# DA14683 register map
Vendor: Dialog; Series: DA14683; File version: 1.2
CPU: CM0 r1p0, little endian, MPU, FPU, 3 interrupt priority bits
Registers are 16-bit, read-write, reset 0x0 unless marked. A register's access mark holds for its fields unless they carry their own. Offsets are from the block's base; [hi:lo] are bit positions; {n}, {i} and the like mark numbered series.

## DEM — DEM registers
Base 0x50002E00
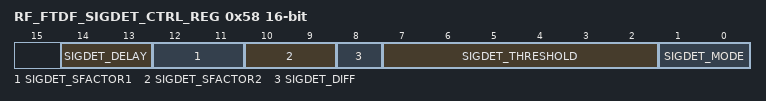
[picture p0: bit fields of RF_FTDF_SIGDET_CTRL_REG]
0x58 RF_FTDF_SIGDET_CTRL_REG
  [14:13] SIGDET_DELAY, [12:11] SIGDET_SFACTOR1, [10:9] SIGDET_SFACTOR2, [8] SIGDET_DIFF, [7:2] SIGDET_THRESHOLD, [1:0] SIGDET_MODE

## GP_TIMERS — GP_TIMERS registers
Base 0x50003400
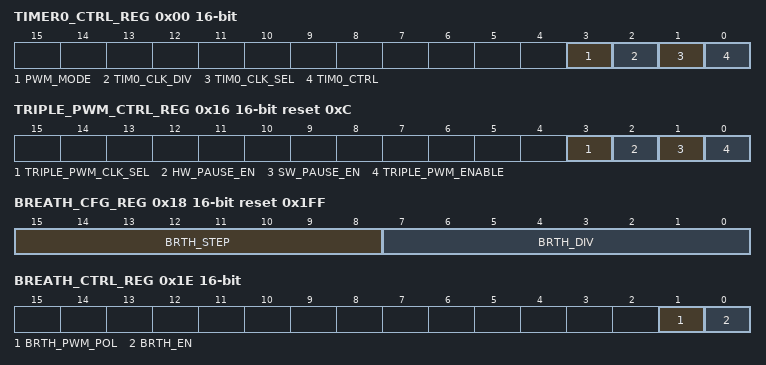
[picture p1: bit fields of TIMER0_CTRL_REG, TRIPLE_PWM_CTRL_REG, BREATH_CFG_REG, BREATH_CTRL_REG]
0x00 TIMER0_CTRL_REG — Timer0 control register
  [3] PWM_MODE — '0' = PWM signals are '1' during high time. '1' = PWM signals send out the (fast) clock divided by 2 during high time.
  [2] TIM0_CLK_DIV — '1' = Timer0 uses selected clock frequency as is. '0' = Timer0 uses selected clock frequency divided by 10. Note that this applies only to the ON-counter.
  [1] TIM0_CLK_SEL — '1' = Timer0 uses fast clock frequency. '0' = Timer0 uses 32 kHz (slow) clock frequency.
  [0] TIM0_CTRL — '0' = Timer0 is off and in reset state. '1' = Timer0 is running.
0x02 TIMER0_ON_REG — Timer0 on control register
  [15:0] TIM0_ON wo — Timer0 On reload value. If read the actual counter value ON_CNTer is returned
0x04 TIMER0_RELOAD_M_REG — 16 bits reload value for Timer0
  [15:0] TIM0_M wo — Timer0 'high' reload value. If read the actual counter value T0_CNTer is returned
0x06 TIMER0_RELOAD_N_REG — 16 bits reload value for Timer0
  [15:0] TIM0_N wo — Timer0 'low' reload value. If read the actual counter value T0_CNTer is returned
{0x4+2i} PWM{i}_START_CYCLE (i=2..4) — Defines start Cycle for PWM{i}
  [13:0] START_CYCLE — Defines the cycle in which the PWM becomes high. if start_cycle is larger than freq or end_cycle is equal to start_cycle, pwm out is always 0
{0xA+2i} PWM{i}_END_CYCLE (i=2..4) — Defines end Cycle for PWM{i}
  [13:0] END_CYCLE — Defines the cycle in which the PWM becomes low. If end_cycle is larger then freq and start_cycle is not larger then freq, output is always 1
0x14 TRIPLE_PWM_FREQUENCY — Defines the PMW2,3,4 frequency
  [13:0] FREQ — Defines the frequency of PWM 2 3 4, period = TMR2_CLK * ( FREQ+1)
0x16 TRIPLE_PWM_CTRL_REG reset 0xC — PWM 2 3 4 Control register
  [3] TRIPLE_PWM_CLK_SEL — '1' = Triple PWM uses fast clock frequency. '0' = Triple PWM uses 32 Khz (slow) clock frequency
  [2] HW_PAUSE_EN — '1' = HW can pause PWM 2,3,4 and BREATH timer
  [1] SW_PAUSE_EN — '1' = PWM 2 3 4 and BREATH timer (if applicable) are paused
  [0] TRIPLE_PWM_ENABLE — '1' = PWM 2 3 4 is enabled
0x18 BREATH_CFG_REG reset 0x1FF — Breath configuration register
  [15:8] BRTH_STEP — Defines the number of PWM periods minus 1, in which duty cycle will be constant
  [7:0] BRTH_DIV — Defines the breath PWM frequecny. Breath PWM frequency is 16MHz / (BRTH_DIV+1)
0x1A BREATH_DUTY_MAX_REG reset 0xA — Breath max duty cycle register
  [7:0] BRTH_DUTY_MAX — Defines the maximum duty cycle of the PWM breath function. Max duty cycle = BRTH_DUTY_MAX / (BRTH_DIV+1)
0x1C BREATH_DUTY_MIN_REG reset 0x1 — Breath min duty cycle register
  [7:0] BRTH_DUTY_MIN — Defines the minimum duty cycle of the PWM breath function. Min duty cycle = BRTH_DUTY_MIN / (BRTH_DIV+1)
0x1E BREATH_CTRL_REG — Breath control register
  [1] BRTH_PWM_POL — Defines the output polarity. '0' line is low in idle state. '1' line is high in idle state.
  [0] BRTH_EN — '1' enable the Breath operation

## IR — IR registers
Base 0x50001700
0x00 IR_FREQ_CARRIER_ON_REG reset 0x1 — Defines the carrier signal high duration
  [9:0] IR_FREQ_CARRIER_ON — Defines the carrier signal high duration in IR_clk cycles. 0x0 is not allowed as a value.
0x02 IR_FREQ_CARRIER_OFF_REG reset 0x1 — Defnes the carrier signal low duration
  [9:0] IR_FREQ_CARRIER_OFF — Defines the carrier signal low duration in IR_clk cycles
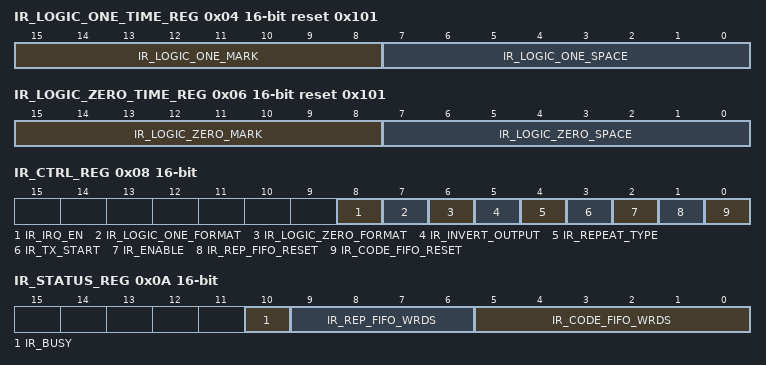
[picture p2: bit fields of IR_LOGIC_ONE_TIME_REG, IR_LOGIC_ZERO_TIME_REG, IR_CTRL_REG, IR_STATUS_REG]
0x04 IR_LOGIC_ONE_TIME_REG reset 0x101 — Defines the logic one waveform
  [15:8] IR_LOGIC_ONE_MARK — Defines the mark duration in carrier clock cycles. Must be >0
  [7:0] IR_LOGIC_ONE_SPACE — Defines the space duration in carrier clock cycles. Must be >0
0x06 IR_LOGIC_ZERO_TIME_REG reset 0x101 — Defines the logic zero wavefrom
  [15:8] IR_LOGIC_ZERO_MARK — Defines the mark duration in carrier clock cycles. Must be >0
  [7:0] IR_LOGIC_ZERO_SPACE — Defines the space duration in carrier clock cycles. Must be >0
0x08 IR_CTRL_REG — IR control register
  [8] IR_IRQ_EN — 1 = Enables the interrupt generation upon TX completion 0 = masks out the interrupt generation upon TX completion
  [7] IR_LOGIC_ONE_FORMAT — 1 = Logic one starts with a Space followed by a Mark 0 = Logic one starts with a Mark followed by a Space
  [6] IR_LOGIC_ZERO_FORMAT — 1 = Logic zero starts with a Space followed by a Mark 0 = Logic zero starts with a Mark followed by a Space
  [5] IR_INVERT_OUTPUT — 1 = IR output is inverted 0 = IR output is not inverted
  [4] IR_REPEAT_TYPE — 1 = repeat command is defined at Repeat FIFO 0 = repeat command is defined at Code FIFO
  [3] IR_TX_START — 1 = IR transmits a command 0 = IR is stopped While this bit is 1 and SW programs it to 0, the code FIFO will be flushed automatically.
  [2] IR_ENABLE — 1 = IR block is enabled 0 = IR block is disabled and at reset state. This also resets the pointers at the FIFOs
  [1] IR_REP_FIFO_RESET wo — 1 = Flush Repeat FIFO (auto clear)
  [0] IR_CODE_FIFO_RESET wo — 1 = Flush Code FIFO (auto clear)
0x0A IR_STATUS_REG — IR status register
  [10] IR_BUSY ro — 1 = IR generator is busy sending a message 0 = IR generator is idle
  [9:6] IR_REP_FIFO_WRDS ro — Contains the amount of words in Repeat FIFO (updated only on write)
  [5:0] IR_CODE_FIFO_WRDS ro — Contains the amount of words in Code FIFO (updated only on write)
0x0C IR_REPEAT_TIME_REG — Defines the repeat time
  [15:0] IR_REPEAT_TIME — Defines the repeat time in carrier clock cycles. The repeat timer will start counting from the start of the command and will trigger the output of the same command residing in the Code FIFO or the special command residing in the Repeat FIFO as soon as it expires.
0x0E IR_MAIN_FIFO_REG — Main fifo write register
  [15:0] IR_CODE_FIFO_DATA wo — Code FIFO data write port
0x10 IR_REPEAT_FIFO_REG — Repeat fifo write register
  [15:0] IR_REPEAT_FIFO_DATA wo — Repeat FIFO data write port
0x12 IR_IRQ_STATUS_REG — IR interrupt status register
  [0] IR_IRQ_ACK ro — When read Interrupt line is cleared
